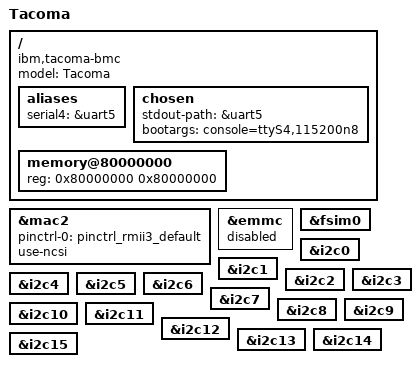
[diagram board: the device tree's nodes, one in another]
// SPDX-License-Identifier: GPL-2.0-or-later
// Copyright 2019 IBM Corp.
/dts-v1/;

#include "aspeed-g6.dtsi"

/ {
	model = "Tacoma";
	compatible = "ibm,tacoma-bmc", "aspeed,ast2600";

	aliases {
		serial4 = &uart5;
	};

	chosen {
		stdout-path = &uart5;
		bootargs = "console=ttyS4,115200n8";
	};

	memory@80000000 {
		device_type = "memory";
		reg = <0x80000000 0x80000000>;
	};
};

&mac2 {
	status = "okay";
	pinctrl-names = "default";
	pinctrl-0 = <&pinctrl_rmii3_default>;
	use-ncsi;
};

&emmc {
	status = "disabled";
};

&fsim0 {
	status = "okay";
};

&i2c0 {
	status = "okay";
};

&i2c1 {
	status = "okay";
};

&i2c2 {
	status = "okay";
};

&i2c3 {
	status = "okay";
};

&i2c4 {
	status = "okay";
};

&i2c5 {
	status = "okay";
};

&i2c6 {
	status = "okay";
};

&i2c7 {
	status = "okay";
};

&i2c8 {
	status = "okay";
};

&i2c9 {
	status = "okay";
};

&i2c10 {
	status = "okay";
};

&i2c11 {
	status = "okay";
};

&i2c12 {
	status = "okay";
};

&i2c13 {
	status = "okay";
};

&i2c14 {
	status = "okay";
};

&i2c15 {
	status = "okay";
};
